AUTOSAR XML (schema 4-3-0)
package /SeatHeater
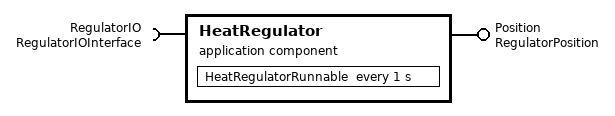
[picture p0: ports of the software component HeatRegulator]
  application sw component type HeatRegulator
    require port RegulatorIO: nonqueued-receiver-com-spec=RegulatorValue, required-interface=RegulatorIOInterface
    provide port Position: nonqueued-sender-com-spec=Position, provided-interface=RegulatorPosition
    behavior HeatRegulator_InternalBehavior
      events:
        timing event HeatRegulatorEvent: start-on-event=HeatRegulatorRunnable, period=1
      runnable HeatRegulatorRunnable
        data-send-points:
          access HeatRegulatorPositionAccess: accessed-variable=Position.Position
        data-receive-point-by-values:
          access HeatRegulatorIOAccess: accessed-variable=RegulatorIO.RegulatorValue
  swc implementation HeatRegulator_Implementation: behavior=HeatRegulator_InternalBehavior
